# MIMXRT1052 register map
Vendor: nxp.com; File version: 1.0
CPU: CM7 r0p1, little endian, MPU, FPU, VTOR, 4 interrupt priority bits
Registers are 32-bit, read-write, reset 0x0 unless marked. A register's access mark holds for its fields unless they carry their own. Offsets are from the block's base; [hi:lo] are bit positions; {n}, {i} and the like mark numbered series; 'fields as' and 'values as' point back to an identical list.

## IOMUXC (part 4 of 4)
Base 0x401F8000; register names take the prefix IOMUXC_
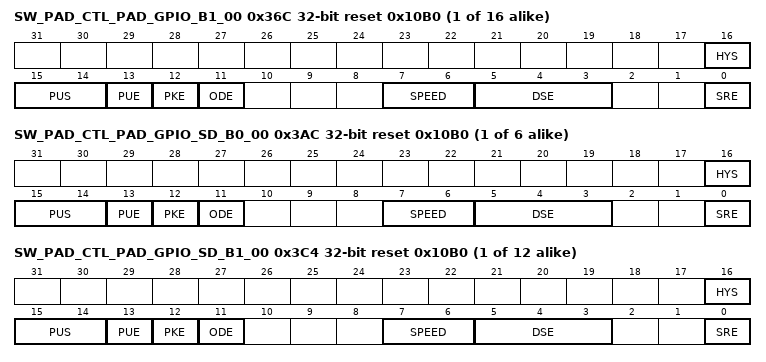
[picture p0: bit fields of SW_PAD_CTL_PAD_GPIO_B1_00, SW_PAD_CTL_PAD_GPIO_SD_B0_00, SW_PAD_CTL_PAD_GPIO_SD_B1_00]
{0x36C+4i} SW_PAD_CTL_PAD_GPIO_B1_{i:02} reset 0x10B0 (i=0..15) — SW_PAD_CTL_PAD_GPIO_B1_{i:02} SW PAD Control Register
  [16] HYS — Hyst. Enable Field
    0=HYS_0_Hysteresis_Disabled (Hysteresis Disabled (CMOS input)); 1=HYS_1_Hysteresis_Enabled (Hysteresis Enabled (Schmitt Trigger input))
  [15:14] PUS — Pull Up / Down Config. Field Controls signals to select pull-up or pull-down internal resistance strength.
    0=PUS_0_100K_Ohm_Pull_Down (100K Ohm Pull Down); 1=PUS_1_47K_Ohm_Pull_Up (47K Ohm Pull Up); 2=PUS_2_100K_Ohm_Pull_Up (100K Ohm Pull Up); 3=PUS_3_22K_Ohm_Pull_Up (22K Ohm Pull Up)
  [13] PUE — Pull / Keep Select Field Control signal to enable internal pull-up/down resistors or pad keeper functionality.
    0=PUE_0_Keeper (Keep the previous output value when the output driver is disabled.); 1=PUE_1_Pull (Pull-up or pull-down (determined by PUS field).)
  [12] PKE — Pull / Keep Enable Field
    0=PKE_0_Pull_Keeper_Disabled (Pull/Keeper Disabled); 1=PKE_1_Pull_Keeper_Enabled (Pull/Keeper Enabled)
  [11] ODE — Open Drain Enable Field
    0=ODE_0_Open_Drain_Disabled (Open Drain Disabled (Output is CMOS)); 1=ODE_1_Open_Drain_Enabled (Open Drain Enabled (Output is Open Drain))
  [7:6] SPEED
    0=SPEED_0_Low (50MHz); 1=SPEED_1_Medium (100MHz - 150MHz); 2=SPEED_2_Medium (100MHz - 150MHz); 3=SPEED_3_Maximum (150MHz - 200MHz)
  [5:3] DSE — Drive Strength Field
    0=HI-Z; 1=Dual/Single voltage: 262/260 Ohm @ 1.8V, 247/157 Ohm @ 3.3V; 2=Dual/Single voltage: 134/130 Ohm @ 1.8V, 126/78 Ohm @ 3.3V; 3=Dual/Single voltage: 88/88 Ohm @ 1.8V, 84/53 Ohm @ 3.3V; 4=Dual/Single voltage: 62/65 Ohm @ 1.8V, 57/39 Ohm @ 3.3V; 5=Dual/Single voltage: 51/52 Ohm @ 1.8V, 47/32 Ohm @ 3.3V; 6=Dual/Single voltage: 43/43 Ohm @ 1.8V, 40/26 Ohm @ 3.3V; 7=Dual/Single voltage: 37/37 Ohm @ 1.8V, 34/23 Ohm @ 3.3V
  [0] SRE — Slew Rate Field
    0=SRE_0_Slow_Slew_Rate (Slow Slew Rate); 1=SRE_1_Fast_Slew_Rate (Fast Slew Rate)
{0x3AC+4i} SW_PAD_CTL_PAD_GPIO_SD_B0_{i:02} reset 0x10B0 (i=0..5) — SW_PAD_CTL_PAD_GPIO_SD_B0_{i:02} SW PAD Control Register
  fields as SW_PAD_CTL_PAD_GPIO_B1_00
{0x3C4+4i} SW_PAD_CTL_PAD_GPIO_SD_B1_{i:02} reset 0x10B0 (i=0..11) — SW_PAD_CTL_PAD_GPIO_SD_B1_{i:02} SW PAD Control Register
  fields as SW_PAD_CTL_PAD_GPIO_B1_00
0x3F4 ANATOP_USB_OTG1_ID_SELECT_INPUT — ANATOP_USB_OTG1_ID_SELECT_INPUT DAISY Register
  [0] DAISY — Selecting Pads Involved in Daisy Chain.
    0=GPIO_AD_B0_01_ALT3 (Selecting Pad: GPIO_AD_B0_01 for Mode: ALT3); 1=GPIO_AD_B1_02_ALT0 (Selecting Pad: GPIO_AD_B1_02 for Mode: ALT0)
0x3F8 ANATOP_USB_OTG2_ID_SELECT_INPUT — ANATOP_USB_OTG2_ID_SELECT_INPUT DAISY Register
  [0] DAISY — Selecting Pads Involved in Daisy Chain.
    0=GPIO_AD_B0_00_ALT3 (Selecting Pad: GPIO_AD_B0_00 for Mode: ALT3); 1=GPIO_AD_B1_00_ALT0 (Selecting Pad: GPIO_AD_B1_00 for Mode: ALT0)
0x3FC CCM_PMIC_READY_SELECT_INPUT — CCM_PMIC_READY_SELECT_INPUT DAISY Register
  [2:0] DAISY — Selecting Pads Involved in Daisy Chain.
    0=GPIO_SD_B1_03_ALT6 (Selecting Pad: GPIO_SD_B1_03 for Mode: ALT6); 1=GPIO_AD_B0_12_ALT1 (Selecting Pad: GPIO_AD_B0_12 for Mode: ALT1); 2=GPIO_AD_B1_01_ALT4 (Selecting Pad: GPIO_AD_B1_01 for Mode: ALT4); 3=GPIO_AD_B1_08_ALT3 (Selecting Pad: GPIO_AD_B1_08 for Mode: ALT3); 4=GPIO_EMC_32_ALT3 (Selecting Pad: GPIO_EMC_32 for Mode: ALT3)
0x400 CSI_DATA02_SELECT_INPUT — CSI_DATA02_SELECT_INPUT DAISY Register
  [0] DAISY — Selecting Pads Involved in Daisy Chain.
    0=GPIO_AD_B1_15_ALT4 (Selecting Pad: GPIO_AD_B1_15 for Mode: ALT4); 1=GPIO_AD_B0_11_ALT4 (Selecting Pad: GPIO_AD_B0_11 for Mode: ALT4)
0x404 CSI_DATA03_SELECT_INPUT — CSI_DATA03_SELECT_INPUT DAISY Register
  [0] DAISY — Selecting Pads Involved in Daisy Chain.
    0=GPIO_AD_B1_14_ALT4 (Selecting Pad: GPIO_AD_B1_14 for Mode: ALT4); 1=GPIO_AD_B0_10_ALT4 (Selecting Pad: GPIO_AD_B0_10 for Mode: ALT4)
0x408 CSI_DATA04_SELECT_INPUT — CSI_DATA04_SELECT_INPUT DAISY Register
  [0] DAISY — Selecting Pads Involved in Daisy Chain.
    0=GPIO_AD_B1_13_ALT4 (Selecting Pad: GPIO_AD_B1_13 for Mode: ALT4); 1=GPIO_AD_B0_09_ALT4 (Selecting Pad: GPIO_AD_B0_09 for Mode: ALT4)
0x40C CSI_DATA05_SELECT_INPUT — CSI_DATA05_SELECT_INPUT DAISY Register
  [0] DAISY — Selecting Pads Involved in Daisy Chain.
    0=GPIO_AD_B1_12_ALT4 (Selecting Pad: GPIO_AD_B1_12 for Mode: ALT4); 1=GPIO_AD_B0_08_ALT4 (Selecting Pad: GPIO_AD_B0_08 for Mode: ALT4)
0x410 CSI_DATA06_SELECT_INPUT — CSI_DATA06_SELECT_INPUT DAISY Register
  [0] DAISY — Selecting Pads Involved in Daisy Chain.
    0=GPIO_AD_B1_11_ALT4 (Selecting Pad: GPIO_AD_B1_11 for Mode: ALT4); 1=GPIO_AD_B0_07_ALT4 (Selecting Pad: GPIO_AD_B0_07 for Mode: ALT4)
0x414 CSI_DATA07_SELECT_INPUT — CSI_DATA07_SELECT_INPUT DAISY Register
  [0] DAISY — Selecting Pads Involved in Daisy Chain.
    0=GPIO_AD_B1_10_ALT4 (Selecting Pad: GPIO_AD_B1_10 for Mode: ALT4); 1=GPIO_AD_B0_06_ALT4 (Selecting Pad: GPIO_AD_B0_06 for Mode: ALT4)
0x418 CSI_DATA08_SELECT_INPUT — CSI_DATA08_SELECT_INPUT DAISY Register
  [0] DAISY — Selecting Pads Involved in Daisy Chain.
    0=GPIO_AD_B1_09_ALT4 (Selecting Pad: GPIO_AD_B1_09 for Mode: ALT4); 1=GPIO_AD_B0_05_ALT4 (Selecting Pad: GPIO_AD_B0_05 for Mode: ALT4)
0x41C CSI_DATA09_SELECT_INPUT — CSI_DATA09_SELECT_INPUT DAISY Register
  [0] DAISY — Selecting Pads Involved in Daisy Chain.
    0=GPIO_AD_B1_08_ALT4 (Selecting Pad: GPIO_AD_B1_08 for Mode: ALT4); 1=GPIO_AD_B0_04_ALT4 (Selecting Pad: GPIO_AD_B0_04 for Mode: ALT4)
0x420 CSI_HSYNC_SELECT_INPUT — CSI_HSYNC_SELECT_INPUT DAISY Register
  [1:0] DAISY — Selecting Pads Involved in Daisy Chain.
    0=GPIO_AD_B0_15_ALT4 (Selecting Pad: GPIO_AD_B0_15 for Mode: ALT4); 1=GPIO_AD_B1_07_ALT4 (Selecting Pad: GPIO_AD_B1_07 for Mode: ALT4); 2=GPIO_B1_14_ALT2 (Selecting Pad: GPIO_B1_14 for Mode: ALT2)
0x424 CSI_PIXCLK_SELECT_INPUT — CSI_PIXCLK_SELECT_INPUT DAISY Register
  [0] DAISY — Selecting Pads Involved in Daisy Chain.
    0=GPIO_AD_B1_04_ALT4 (Selecting Pad: GPIO_AD_B1_04 for Mode: ALT4); 1=GPIO_B1_12_ALT2 (Selecting Pad: GPIO_B1_12 for Mode: ALT2)
0x428 CSI_VSYNC_SELECT_INPUT — CSI_VSYNC_SELECT_INPUT DAISY Register
  [1:0] DAISY — Selecting Pads Involved in Daisy Chain.
    0=GPIO_AD_B0_14_ALT4 (Selecting Pad: GPIO_AD_B0_14 for Mode: ALT4); 1=GPIO_AD_B1_06_ALT4 (Selecting Pad: GPIO_AD_B1_06 for Mode: ALT4); 2=GPIO_B1_13_ALT2 (Selecting Pad: GPIO_B1_13 for Mode: ALT2)
0x42C ENET_IPG_CLK_RMII_SELECT_INPUT — ENET_IPG_CLK_RMII_SELECT_INPUT DAISY Register
  [0] DAISY — Selecting Pads Involved in Daisy Chain.
    0=GPIO_EMC_25_ALT4 (Selecting Pad: GPIO_EMC_25 for Mode: ALT4); 1=GPIO_B1_10_ALT6 (Selecting Pad: GPIO_B1_10 for Mode: ALT6)
0x430 ENET_MDIO_SELECT_INPUT — ENET_MDIO_SELECT_INPUT DAISY Register
  [1:0] DAISY — Selecting Pads Involved in Daisy Chain.
    0=GPIO_AD_B1_05_ALT1 (Selecting Pad: GPIO_AD_B1_05 for Mode: ALT1); 1=GPIO_EMC_41_ALT4 (Selecting Pad: GPIO_EMC_41 for Mode: ALT4); 2=GPIO_B1_15_ALT0 (Selecting Pad: GPIO_B1_15 for Mode: ALT0)
0x434 ENET0_RXDATA_SELECT_INPUT — ENET0_RXDATA_SELECT_INPUT DAISY Register
  [0] DAISY — Selecting Pads Involved in Daisy Chain.
    0=GPIO_EMC_20_ALT3 (Selecting Pad: GPIO_EMC_20 for Mode: ALT3); 1=GPIO_B1_04_ALT3 (Selecting Pad: GPIO_B1_04 for Mode: ALT3)
0x438 ENET1_RXDATA_SELECT_INPUT — ENET1_RXDATA_SELECT_INPUT DAISY Register
  [0] DAISY — Selecting Pads Involved in Daisy Chain.
    0=GPIO_EMC_19_ALT3 (Selecting Pad: GPIO_EMC_19 for Mode: ALT3); 1=GPIO_B1_05_ALT3 (Selecting Pad: GPIO_B1_05 for Mode: ALT3)
0x43C ENET_RXEN_SELECT_INPUT — ENET_RXEN_SELECT_INPUT DAISY Register
  [0] DAISY — Selecting Pads Involved in Daisy Chain.
    0=GPIO_EMC_23_ALT3 (Selecting Pad: GPIO_EMC_23 for Mode: ALT3); 1=GPIO_B1_06_ALT3 (Selecting Pad: GPIO_B1_06 for Mode: ALT3)
0x440 ENET_RXERR_SELECT_INPUT — ENET_RXERR_SELECT_INPUT DAISY Register
  [0] DAISY — Selecting Pads Involved in Daisy Chain.
    0=GPIO_EMC_26_ALT3 (Selecting Pad: GPIO_EMC_26 for Mode: ALT3); 1=GPIO_B1_11_ALT3 (Selecting Pad: GPIO_B1_11 for Mode: ALT3)
0x444 ENET0_TIMER_SELECT_INPUT — ENET0_TIMER_SELECT_INPUT DAISY Register
  [1:0] DAISY — Selecting Pads Involved in Daisy Chain.
    0=GPIO_AD_B0_15_ALT3 (Selecting Pad: GPIO_AD_B0_15 for Mode: ALT3); 1=GPIO_AD_B0_11_ALT7 (Selecting Pad: GPIO_AD_B0_11 for Mode: ALT7); 2=GPIO_B1_12_ALT3 (Selecting Pad: GPIO_B1_12 for Mode: ALT3)
0x448 ENET_TXCLK_SELECT_INPUT — ENET_TXCLK_SELECT_INPUT DAISY Register
  [0] DAISY — Selecting Pads Involved in Daisy Chain.
    0=GPIO_EMC_25_ALT3 (Selecting Pad: GPIO_EMC_25 for Mode: ALT3); 1=GPIO_B1_10_ALT3 (Selecting Pad: GPIO_B1_10 for Mode: ALT3)
0x44C FLEXCAN1_RX_SELECT_INPUT — FLEXCAN1_RX_SELECT_INPUT DAISY Register
  [1:0] DAISY — Selecting Pads Involved in Daisy Chain.
    0=GPIO_SD_B1_03_ALT4 (Selecting Pad: GPIO_SD_B1_03 for Mode: ALT4); 1=GPIO_EMC_18_ALT3 (Selecting Pad: GPIO_EMC_18 for Mode: ALT3); 2=GPIO_AD_B1_09_ALT2 (Selecting Pad: GPIO_AD_B1_09 for Mode: ALT2); 3=GPIO_B0_03_ALT2 (Selecting Pad: GPIO_B0_03 for Mode: ALT2)
0x450 FLEXCAN2_RX_SELECT_INPUT — FLEXCAN2_RX_SELECT_INPUT DAISY Register
  [1:0] DAISY — Selecting Pads Involved in Daisy Chain.
    0=GPIO_EMC_10_ALT3 (Selecting Pad: GPIO_EMC_10 for Mode: ALT3); 1=GPIO_AD_B0_03_ALT0 (Selecting Pad: GPIO_AD_B0_03 for Mode: ALT0); 2=GPIO_AD_B0_15_ALT6 (Selecting Pad: GPIO_AD_B0_15 for Mode: ALT6); 3=GPIO_B1_09_ALT6 (Selecting Pad: GPIO_B1_09 for Mode: ALT6)
0x454 FLEXPWM1_PWMA3_SELECT_INPUT — FLEXPWM1_PWMA3_SELECT_INPUT DAISY Register
  [2:0] DAISY — Selecting Pads Involved in Daisy Chain.
    0=GPIO_SD_B1_00_ALT2 (Selecting Pad: GPIO_SD_B1_00 for Mode: ALT2); 1=GPIO_EMC_12_ALT4 (Selecting Pad: GPIO_EMC_12 for Mode: ALT4); 2=GPIO_EMC_38_ALT1 (Selecting Pad: GPIO_EMC_38 for Mode: ALT1); 3=GPIO_AD_B0_10_ALT1 (Selecting Pad: GPIO_AD_B0_10 for Mode: ALT1); 4=GPIO_B1_00_ALT6 (Selecting Pad: GPIO_B1_00 for Mode: ALT6)
{0x458+4i} FLEXPWM1_PWMA{i}_SELECT_INPUT (i=0..2) — FLEXPWM1_PWMA{i}_SELECT_INPUT DAISY Register
  [0] DAISY — Selecting Pads Involved in Daisy Chain.
    0=GPIO_EMC_{2i+23}_ALT1 (Selecting Pad: GPIO_EMC_{2i+23} for Mode: ALT1); 1=GPIO_SD_B0_{2i:02}_ALT1 (Selecting Pad: GPIO_SD_B0_{2i:02} for Mode: ALT1)
0x464 FLEXPWM1_PWMB3_SELECT_INPUT — FLEXPWM1_PWMB3_SELECT_INPUT DAISY Register
  [2:0] DAISY — Selecting Pads Involved in Daisy Chain.
    0=GPIO_SD_B1_01_ALT2 (Selecting Pad: GPIO_SD_B1_01 for Mode: ALT2); 1=GPIO_EMC_13_ALT4 (Selecting Pad: GPIO_EMC_13 for Mode: ALT4); 2=GPIO_EMC_39_ALT1 (Selecting Pad: GPIO_EMC_39 for Mode: ALT1); 3=GPIO_AD_B0_11_ALT1 (Selecting Pad: GPIO_AD_B0_11 for Mode: ALT1); 4=GPIO_B1_01_ALT6 (Selecting Pad: GPIO_B1_01 for Mode: ALT6)
{0x468+4i} FLEXPWM1_PWMB{i}_SELECT_INPUT (i=0..2) — FLEXPWM1_PWMB{i}_SELECT_INPUT DAISY Register
  [0] DAISY — Selecting Pads Involved in Daisy Chain.
    0=GPIO_EMC_{2i+24}_ALT1 (Selecting Pad: GPIO_EMC_{2i+24} for Mode: ALT1); 1=GPIO_SD_B0_{2i+1:02}_ALT1 (Selecting Pad: GPIO_SD_B0_{2i+1:02} for Mode: ALT1)
0x474 FLEXPWM2_PWMA3_SELECT_INPUT — FLEXPWM2_PWMA3_SELECT_INPUT DAISY Register
  [2:0] DAISY — Selecting Pads Involved in Daisy Chain.
    0=GPIO_SD_B1_02_ALT2 (Selecting Pad: GPIO_SD_B1_02 for Mode: ALT2); 1=GPIO_EMC_19_ALT1 (Selecting Pad: GPIO_EMC_19 for Mode: ALT1); 2=GPIO_AD_B0_00_ALT0 (Selecting Pad: GPIO_AD_B0_00 for Mode: ALT0); 3=GPIO_AD_B0_09_ALT1 (Selecting Pad: GPIO_AD_B0_09 for Mode: ALT1); 4=GPIO_B1_02_ALT6 (Selecting Pad: GPIO_B1_02 for Mode: ALT6)
{0x478+4i} FLEXPWM2_PWMA{i}_SELECT_INPUT (i=0..2) — FLEXPWM2_PWMA{i}_SELECT_INPUT DAISY Register
  [0] DAISY — Selecting Pads Involved in Daisy Chain.
    0=GPIO_EMC_{2i+6:02}_ALT1 (Selecting Pad: GPIO_EMC_{2i+6:02} for Mode: ALT1); 1=GPIO_B0_{2i+6:02}_ALT2 (Selecting Pad: GPIO_B0_{2i+6:02} for Mode: ALT2)
0x484 FLEXPWM2_PWMB3_SELECT_INPUT — FLEXPWM2_PWMB3_SELECT_INPUT DAISY Register
  [1:0] DAISY — Selecting Pads Involved in Daisy Chain.
    0=GPIO_SD_B1_03_ALT2 (Selecting Pad: GPIO_SD_B1_03 for Mode: ALT2); 1=GPIO_EMC_20_ALT1 (Selecting Pad: GPIO_EMC_20 for Mode: ALT1); 2=GPIO_AD_B0_01_ALT0 (Selecting Pad: GPIO_AD_B0_01 for Mode: ALT0); 3=GPIO_B1_03_ALT6 (Selecting Pad: GPIO_B1_03 for Mode: ALT6)
{0x488+4i} FLEXPWM2_PWMB{i}_SELECT_INPUT (i=0..2) — FLEXPWM2_PWMB{i}_SELECT_INPUT DAISY Register
  [0] DAISY — Selecting Pads Involved in Daisy Chain.
    0=GPIO_EMC_{2i+7:02}_ALT1 (Selecting Pad: GPIO_EMC_{2i+7:02} for Mode: ALT1); 1=GPIO_B0_{2i+7:02}_ALT2 (Selecting Pad: GPIO_B0_{2i+7:02} for Mode: ALT2)
0x494 FLEXPWM4_PWMA0_SELECT_INPUT — FLEXPWM4_PWMA0_SELECT_INPUT DAISY Register
  [0] DAISY — Selecting Pads Involved in Daisy Chain.
    0=GPIO_EMC_00_ALT1 (Selecting Pad: GPIO_EMC_00 for Mode: ALT1); 1=GPIO_AD_B1_08_ALT1 (Selecting Pad: GPIO_AD_B1_08 for Mode: ALT1)
0x498 FLEXPWM4_PWMA1_SELECT_INPUT — FLEXPWM4_PWMA1_SELECT_INPUT DAISY Register
  [0] DAISY — Selecting Pads Involved in Daisy Chain.
    0=GPIO_EMC_02_ALT1 (Selecting Pad: GPIO_EMC_02 for Mode: ALT1); 1=GPIO_AD_B1_09_ALT1 (Selecting Pad: GPIO_AD_B1_09 for Mode: ALT1)
0x49C FLEXPWM4_PWMA2_SELECT_INPUT — FLEXPWM4_PWMA2_SELECT_INPUT DAISY Register
  [0] DAISY — Selecting Pads Involved in Daisy Chain.
    0=GPIO_EMC_04_ALT1 (Selecting Pad: GPIO_EMC_04 for Mode: ALT1); 1=GPIO_B1_14_ALT1 (Selecting Pad: GPIO_B1_14 for Mode: ALT1)
0x4A0 FLEXPWM4_PWMA3_SELECT_INPUT — FLEXPWM4_PWMA3_SELECT_INPUT DAISY Register
  [0] DAISY — Selecting Pads Involved in Daisy Chain.
    0=GPIO_EMC_17_ALT1 (Selecting Pad: GPIO_EMC_17 for Mode: ALT1); 1=GPIO_B1_15_ALT1 (Selecting Pad: GPIO_B1_15 for Mode: ALT1)
0x4A4 FLEXSPI_A_DQS_SELECT_INPUT — FLEXSPI_A_DQS_SELECT_INPUT DAISY Register
  [0] DAISY — Selecting Pads Involved in Daisy Chain.
    0=GPIO_SD_B1_05_ALT1 (Selecting Pad: GPIO_SD_B1_05 for Mode: ALT1); 1=GPIO_AD_B1_09_ALT0 (Selecting Pad: GPIO_AD_B1_09 for Mode: ALT0)
0x4A8 FLEXSPI_A_DATA0_SELECT_INPUT — FLEXSPI_A_DATA0_SELECT_INPUT DAISY Register
  [0] DAISY — Selecting Pads Involved in Daisy Chain.
    0=GPIO_SD_B1_08_ALT1 (Selecting Pad: GPIO_SD_B1_08 for Mode: ALT1); 1=GPIO_AD_B1_13_ALT0 (Selecting Pad: GPIO_AD_B1_13 for Mode: ALT0)
0x4AC FLEXSPI_A_DATA1_SELECT_INPUT — FLEXSPI_A_DATA1_SELECT_INPUT DAISY Register
  [0] DAISY — Selecting Pads Involved in Daisy Chain.
    0=GPIO_SD_B1_09_ALT1 (Selecting Pad: GPIO_SD_B1_09 for Mode: ALT1); 1=GPIO_AD_B1_12_ALT0 (Selecting Pad: GPIO_AD_B1_12 for Mode: ALT0)
0x4B0 FLEXSPI_A_DATA2_SELECT_INPUT — FLEXSPI_A_DATA2_SELECT_INPUT DAISY Register
  [0] DAISY — Selecting Pads Involved in Daisy Chain.
    0=GPIO_SD_B1_10_ALT1 (Selecting Pad: GPIO_SD_B1_10 for Mode: ALT1); 1=GPIO_AD_B1_11_ALT0 (Selecting Pad: GPIO_AD_B1_11 for Mode: ALT0)
0x4B4 FLEXSPI_A_DATA3_SELECT_INPUT — FLEXSPI_A_DATA3_SELECT_INPUT DAISY Register
  [0] DAISY — Selecting Pads Involved in Daisy Chain.
    0=GPIO_SD_B1_11_ALT1 (Selecting Pad: GPIO_SD_B1_11 for Mode: ALT1); 1=GPIO_AD_B1_10_ALT0 (Selecting Pad: GPIO_AD_B1_10 for Mode: ALT0)
0x4B8 FLEXSPI_B_DATA0_SELECT_INPUT — FLEXSPI_B_DATA0_SELECT_INPUT DAISY Register
  [0] DAISY — Selecting Pads Involved in Daisy Chain.
    0=GPIO_SD_B1_03_ALT1 (Selecting Pad: GPIO_SD_B1_03 for Mode: ALT1); 1=GPIO_AD_B1_07_ALT0 (Selecting Pad: GPIO_AD_B1_07 for Mode: ALT0)
0x4BC FLEXSPI_B_DATA1_SELECT_INPUT — FLEXSPI_B_DATA1_SELECT_INPUT DAISY Register
  [0] DAISY — Selecting Pads Involved in Daisy Chain.
    0=GPIO_SD_B1_02_ALT1 (Selecting Pad: GPIO_SD_B1_02 for Mode: ALT1); 1=GPIO_AD_B1_06_ALT0 (Selecting Pad: GPIO_AD_B1_06 for Mode: ALT0)
0x4C0 FLEXSPI_B_DATA2_SELECT_INPUT — FLEXSPI_B_DATA2_SELECT_INPUT DAISY Register
  [0] DAISY — Selecting Pads Involved in Daisy Chain.
    0=GPIO_SD_B1_01_ALT1 (Selecting Pad: GPIO_SD_B1_01 for Mode: ALT1); 1=GPIO_AD_B1_05_ALT0 (Selecting Pad: GPIO_AD_B1_05 for Mode: ALT0)
0x4C4 FLEXSPI_B_DATA3_SELECT_INPUT — FLEXSPI_B_DATA3_SELECT_INPUT DAISY Register
  [0] DAISY — Selecting Pads Involved in Daisy Chain.
    0=GPIO_SD_B1_00_ALT1 (Selecting Pad: GPIO_SD_B1_00 for Mode: ALT1); 1=GPIO_AD_B1_04_ALT0 (Selecting Pad: GPIO_AD_B1_04 for Mode: ALT0)
0x4C8 FLEXSPI_A_SCK_SELECT_INPUT — FLEXSPI_A_SCK_SELECT_INPUT DAISY Register
  [0] DAISY — Selecting Pads Involved in Daisy Chain.
    0=GPIO_SD_B1_07_ALT1 (Selecting Pad: GPIO_SD_B1_07 for Mode: ALT1); 1=GPIO_AD_B1_14_ALT0 (Selecting Pad: GPIO_AD_B1_14 for Mode: ALT0)
0x4CC LPI2C1_SCL_SELECT_INPUT — LPI2C1_SCL_SELECT_INPUT DAISY Register
  [0] DAISY — Selecting Pads Involved in Daisy Chain.
    0=GPIO_SD_B1_04_ALT2 (Selecting Pad: GPIO_SD_B1_04 for Mode: ALT2); 1=GPIO_AD_B1_00_ALT3 (Selecting Pad: GPIO_AD_B1_00 for Mode: ALT3)
0x4D0 LPI2C1_SDA_SELECT_INPUT — LPI2C1_SDA_SELECT_INPUT DAISY Register
  [0] DAISY — Selecting Pads Involved in Daisy Chain.
    0=GPIO_SD_B1_05_ALT2 (Selecting Pad: GPIO_SD_B1_05 for Mode: ALT2); 1=GPIO_AD_B1_01_ALT3 (Selecting Pad: GPIO_AD_B1_01 for Mode: ALT3)
0x4D4 LPI2C2_SCL_SELECT_INPUT — LPI2C2_SCL_SELECT_INPUT DAISY Register
  [0] DAISY — Selecting Pads Involved in Daisy Chain.
    0=GPIO_SD_B1_11_ALT3 (Selecting Pad: GPIO_SD_B1_11 for Mode: ALT3); 1=GPIO_B0_04_ALT2 (Selecting Pad: GPIO_B0_04 for Mode: ALT2)
0x4D8 LPI2C2_SDA_SELECT_INPUT — LPI2C2_SDA_SELECT_INPUT DAISY Register
  [0] DAISY — Selecting Pads Involved in Daisy Chain.
    0=GPIO_SD_B1_10_ALT3 (Selecting Pad: GPIO_SD_B1_10 for Mode: ALT3); 1=GPIO_B0_05_ALT2 (Selecting Pad: GPIO_B0_05 for Mode: ALT2)
0x4DC LPI2C3_SCL_SELECT_INPUT — LPI2C3_SCL_SELECT_INPUT DAISY Register
  [1:0] DAISY — Selecting Pads Involved in Daisy Chain.
    0=GPIO_EMC_22_ALT2 (Selecting Pad: GPIO_EMC_22 for Mode: ALT2); 1=GPIO_SD_B0_00_ALT2 (Selecting Pad: GPIO_SD_B0_00 for Mode: ALT2); 2=GPIO_AD_B1_07_ALT1 (Selecting Pad: GPIO_AD_B1_07 for Mode: ALT1)
0x4E0 LPI2C3_SDA_SELECT_INPUT — LPI2C3_SDA_SELECT_INPUT DAISY Register
  [1:0] DAISY — Selecting Pads Involved in Daisy Chain.
    0=GPIO_EMC_21_ALT2 (Selecting Pad: GPIO_EMC_21 for Mode: ALT2); 1=GPIO_SD_B0_01_ALT2 (Selecting Pad: GPIO_SD_B0_01 for Mode: ALT2); 2=GPIO_AD_B1_06_ALT1 (Selecting Pad: GPIO_AD_B1_06 for Mode: ALT1)
0x4E4 LPI2C4_SCL_SELECT_INPUT — LPI2C4_SCL_SELECT_INPUT DAISY Register
  [0] DAISY — Selecting Pads Involved in Daisy Chain.
    0=GPIO_EMC_12_ALT2 (Selecting Pad: GPIO_EMC_12 for Mode: ALT2); 1=GPIO_AD_B0_12_ALT0 (Selecting Pad: GPIO_AD_B0_12 for Mode: ALT0)
0x4E8 LPI2C4_SDA_SELECT_INPUT — LPI2C4_SDA_SELECT_INPUT DAISY Register
  [0] DAISY — Selecting Pads Involved in Daisy Chain.
    0=GPIO_EMC_11_ALT2 (Selecting Pad: GPIO_EMC_11 for Mode: ALT2); 1=GPIO_AD_B0_13_ALT0 (Selecting Pad: GPIO_AD_B0_13 for Mode: ALT0)
0x4EC LPSPI1_PCS0_SELECT_INPUT — LPSPI1_PCS0_SELECT_INPUT DAISY Register
  [0] DAISY — Selecting Pads Involved in Daisy Chain.
    0=GPIO_SD_B0_01_ALT4 (Selecting Pad: GPIO_SD_B0_01 for Mode: ALT4); 1=GPIO_EMC_30_ALT3 (Selecting Pad: GPIO_EMC_30 for Mode: ALT3)
0x4F0 LPSPI1_SCK_SELECT_INPUT — LPSPI1_SCK_SELECT_INPUT DAISY Register
  [0] DAISY — Selecting Pads Involved in Daisy Chain.
    0=GPIO_EMC_27_ALT3 (Selecting Pad: GPIO_EMC_27 for Mode: ALT3); 1=GPIO_SD_B0_00_ALT4 (Selecting Pad: GPIO_SD_B0_00 for Mode: ALT4)
0x4F4 LPSPI1_SDI_SELECT_INPUT — LPSPI1_SDI_SELECT_INPUT DAISY Register
  [0] DAISY — Selecting Pads Involved in Daisy Chain.
    0=GPIO_EMC_29_ALT3 (Selecting Pad: GPIO_EMC_29 for Mode: ALT3); 1=GPIO_SD_B0_03_ALT4 (Selecting Pad: GPIO_AD_B0_03 for Mode: ALT4)
0x4F8 LPSPI1_SDO_SELECT_INPUT — LPSPI1_SDO_SELECT_INPUT DAISY Register
  [0] DAISY — Selecting Pads Involved in Daisy Chain.
    0=GPIO_EMC_28_ALT3 (Selecting Pad: GPIO_EMC_28 for Mode: ALT3); 1=GPIO_SD_B0_02_ALT4 (Selecting Pad: GPIO_SD_B0_02 for Mode: ALT4)
0x4FC LPSPI2_PCS0_SELECT_INPUT — LPSPI2_PCS0_SELECT_INPUT DAISY Register
  [0] DAISY — Selecting Pads Involved in Daisy Chain.
    0=GPIO_SD_B1_06_ALT4 (Selecting Pad: GPIO_SD_B1_06 for Mode: ALT4); 1=GPIO_EMC_01_ALT2 (Selecting Pad: GPIO_EMC_01 for Mode: ALT2)
0x500 LPSPI2_SCK_SELECT_INPUT — LPSPI2_SCK_SELECT_INPUT DAISY Register
  [0] DAISY — Selecting Pads Involved in Daisy Chain.
    0=GPIO_SD_B1_07_ALT4 (Selecting Pad: GPIO_SD_B1_07 for Mode: ALT4); 1=GPIO_EMC_00_ALT2 (Selecting Pad: GPIO_EMC_00 for Mode: ALT2)
0x504 LPSPI2_SDI_SELECT_INPUT — LPSPI2_SDI_SELECT_INPUT DAISY Register
  [0] DAISY — Selecting Pads Involved in Daisy Chain.
    0=GPIO_SD_B1_09_ALT4 (Selecting Pad: GPIO_SD_B1_09 for Mode: ALT4); 1=GPIO_EMC_03_ALT2 (Selecting Pad: GPIO_EMC_03 for Mode: ALT2)
0x508 LPSPI2_SDO_SELECT_INPUT — LPSPI2_SDO_SELECT_INPUT DAISY Register
  [0] DAISY — Selecting Pads Involved in Daisy Chain.
    0=GPIO_SD_B1_08_ALT4 (Selecting Pad: GPIO_SD_B1_08 for Mode: ALT4); 1=GPIO_EMC_02_ALT2 (Selecting Pad: GPIO_EMC_02 for Mode: ALT2)
0x50C LPSPI3_PCS0_SELECT_INPUT — LPSPI3_PCS0_SELECT_INPUT DAISY Register
  [0] DAISY — Selecting Pads Involved in Daisy Chain.
    0=GPIO_AD_B0_03_ALT7 (Selecting Pad: GPIO_AD_B0_03 for Mode: ALT7); 1=GPIO_AD_B1_12_ALT2 (Selecting Pad: GPIO_AD_B1_12 for Mode: ALT2)
0x510 LPSPI3_SCK_SELECT_INPUT — LPSPI3_SCK_SELECT_INPUT DAISY Register
  [0] DAISY — Selecting Pads Involved in Daisy Chain.
    0=GPIO_AD_B0_00_ALT7 (Selecting Pad: GPIO_AD_B0_00 for Mode: ALT7); 1=GPIO_AD_B1_15 (Selecting Pad: GPIO_AD_B1_15 for Mode: ALT2)
0x514 LPSPI3_SDI_SELECT_INPUT — LPSPI3_SDI_SELECT_INPUT DAISY Register
  [0] DAISY — Selecting Pads Involved in Daisy Chain.
    0=GPIO_AD_B0_02_ALT7 (Selecting Pad: GPIO_AD_B0_02 for Mode: ALT7); 1=GPIO_AD_B1_13_ALT2 (Selecting Pad: GPIO_AD_B1_13 for Mode: ALT2)
0x518 LPSPI3_SDO_SELECT_INPUT — LPSPI3_SDO_SELECT_INPUT DAISY Register
  [0] DAISY — Selecting Pads Involved in Daisy Chain.
    0=GPIO_AD_B0_01_ALT7 (Selecting Pad: GPIO_AD_B0_01 for Mode: ALT7); 1=GPIO_AD_B1_14_ALT2 (Selecting Pad: GPIO_AD_B1_14 for Mode: ALT2)
0x51C LPSPI4_PCS0_SELECT_INPUT — LPSPI4_PCS0_SELECT_INPUT DAISY Register
  [0] DAISY — Selecting Pads Involved in Daisy Chain.
    0=GPIO_B0_00_ALT3 (Selecting Pad: GPIO_B0_00 for Mode: ALT3); 1=GPIO_B1_04_ALT1 (Selecting Pad:GPIO_B1_04 for Mode: ALT1)
0x520 LPSPI4_SCK_SELECT_INPUT — LPSPI4_SCK_SELECT_INPUT DAISY Register
  [0] DAISY — Selecting Pads Involved in Daisy Chain.
    0=GPIO_B0_03_ALT3 (Selecting Pad: GPIO_B0_03 for Mode: ALT3); 1=GPIO_B1_07_ALT1 (Selecting Pad: GPIO_B1_07 for Mode: ALT1)
0x524 LPSPI4_SDI_SELECT_INPUT — LPSPI4_SDI_SELECT_INPUT DAISY Register
  [0] DAISY — Selecting Pads Involved in Daisy Chain.
    0=GPIO_B0_01_ALT3 (Selecting Pad: GPIO_B0_01 for Mode: ALT3); 1=GPIO_B1_05_ALT1 (Selecting Pad: GPIO_B1_05 for Mode: ALT1)
0x528 LPSPI4_SDO_SELECT_INPUT — LPSPI4_SDO_SELECT_INPUT DAISY Register
  [0] DAISY — Selecting Pads Involved in Daisy Chain.
    0=GPIO_B0_02_ALT3 (Selecting Pad: GPIO_B0_02 for Mode: ALT3); 1=GPIO_B1_06_ALT1 (Selecting Pad: GPIO_B1_06 for Mode: ALT1)
0x52C LPUART2_RX_SELECT_INPUT — LPUART2_RX_SELECT_INPUT DAISY Register
  [0] DAISY — Selecting Pads Involved in Daisy Chain.
    0=GPIO_SD_B1_10_ALT2 (Selecting Pad: GPIO_SD_B1_10 for Mode: ALT2); 1=GPIO_AD_B1_03_ALT2 (Selecting Pad: GPIO_AD_B1_03 for Mode: ALT2)
0x530 LPUART2_TX_SELECT_INPUT — LPUART2_TX_SELECT_INPUT DAISY Register
  [0] DAISY — Selecting Pads Involved in Daisy Chain.
    0=GPIO_SD_B1_11_ALT2 (Selecting Pad: GPIO_SD_B1_11 for Mode: ALT2); 1=GPIO_AD_B1_02_ALT2 (Selecting Pad: GPIO_AD_B1_02 for Mode: ALT2)
0x534 LPUART3_CTS_B_SELECT_INPUT — LPUART3_CTS_B_SELECT_INPUT DAISY Register
  [0] DAISY — Selecting Pads Involved in Daisy Chain.
    0=GPIO_EMC_15_ALT2 (Selecting Pad: GPIO_EMC_15 for Mode: ALT2); 1=GPIO_AD_B1_04_ALT2 (Selecting Pad: GPIO_AD_B1_04 for Mode: ALT2)
0x538 LPUART3_RX_SELECT_INPUT — LPUART3_RX_SELECT_INPUT DAISY Register
  [1:0] DAISY — Selecting Pads Involved in Daisy Chain.
    0=GPIO_AD_B1_07_ALT2 (Selecting Pad: GPIO_AD_B1_07 for Mode: ALT2); 1=GPIO_EMC_14_ALT2 (Selecting Pad: GPIO_EMC_14 for Mode: ALT2); 2=GPIO_B0_09_ALT3 (Selecting Pad: GPIO_B0_09 for Mode: ALT3)
0x53C LPUART3_TX_SELECT_INPUT — LPUART3_TX_SELECT_INPUT DAISY Register
  [1:0] DAISY — Selecting Pads Involved in Daisy Chain.
    0=GPIO_AD_B1_06_ALT2 (Selecting Pad: GPIO_AD_B1_06 for Mode: ALT2); 1=GPIO_EMC_13_ALT2 (Selecting Pad: GPIO_EMC_13 for Mode: ALT2); 2=GPIO_B0_08_ALT3 (Selecting Pad: GPIO_B0_08 for Mode: ALT3)
0x540 LPUART4_RX_SELECT_INPUT — LPUART4_RX_SELECT_INPUT DAISY Register
  [1:0] DAISY — Selecting Pads Involved in Daisy Chain.
    0=GPIO_SD_B1_01_ALT4 (Selecting Pad: GPIO_SD_B1_01 for Mode: ALT4); 1=GPIO_EMC_20_ALT2 (Selecting Pad: GPIO_EMC_20 for Mode: ALT2); 2=GPIO_B1_01_ALT2 (Selecting Pad: GPIO_B1_01 for Mode: ALT2)
0x544 LPUART4_TX_SELECT_INPUT — LPUART4_TX_SELECT_INPUT DAISY Register
  [1:0] DAISY — Selecting Pads Involved in Daisy Chain.
    0=GPIO_SD_B1_00_ALT4 (Selecting Pad: GPIO_SD_B1_00 for Mode: ALT4); 1=GPIO_EMC_19_ALT2 (Selecting Pad: GPIO_EMC_19 for Mode: ALT2); 2=GPIO_B1_00_ALT2 (Selecting Pad: GPIO_B1_00 for Mode: ALT2)
0x548 LPUART5_RX_SELECT_INPUT — LPUART5_RX_SELECT_INPUT DAISY Register
  [0] DAISY — Selecting Pads Involved in Daisy Chain.
    0=GPIO_EMC_24_ALT2 (Selecting Pad: GPIO_EMC_24 for Mode: ALT2); 1=GPIO_B1_13_ALT1 (Selecting Pad: GPIO_B1_13 for Mode: ALT1)
0x54C LPUART5_TX_SELECT_INPUT — LPUART5_TX_SELECT_INPUT DAISY Register
  [0] DAISY — Selecting Pads Involved in Daisy Chain.
    0=GPIO_EMC_23_ALT2 (Selecting Pad: GPIO_EMC_23 for Mode: ALT2); 1=GPIO_B1_12_ALT1 (Selecting Pad: GPIO_B1_12 for Mode: ALT1)
0x550 LPUART6_RX_SELECT_INPUT — LPUART6_RX_SELECT_INPUT DAISY Register
  [0] DAISY — Selecting Pads Involved in Daisy Chain.
    0=GPIO_EMC_26_ALT2 (Selecting Pad: GPIO_EMC_26 for Mode: ALT2); 1=GPIO_AD_B0_03_ALT2 (Selecting Pad: GPIO_AD_B0_03 for Mode: ALT2)
0x554 LPUART6_TX_SELECT_INPUT — LPUART6_TX_SELECT_INPUT DAISY Register
  [0] DAISY — Selecting Pads Involved in Daisy Chain.
    0=GPIO_EMC_25_ALT2 (Selecting Pad: GPIO_EMC_25 for Mode: ALT2); 1=GPIO_AD_B0_02_ALT2 (Selecting Pad: GPIO_AD_B0_02 for Mode: ALT2)
0x558 LPUART7_RX_SELECT_INPUT — LPUART7_RX_SELECT_INPUT DAISY Register
  [0] DAISY — Selecting Pads Involved in Daisy Chain.
    0=GPIO_SD_B1_09_ALT2 (Selecting Pad: GPIO_SD_B1_09 for Mode: ALT2); 1=GPIO_EMC_32_ALT2 (Selecting Pad: GPIO_EMC_32 for Mode: ALT2)
0x55C LPUART7_TX_SELECT_INPUT — LPUART7_TX_SELECT_INPUT DAISY Register
  [0] DAISY — Selecting Pads Involved in Daisy Chain.
    0=GPIO_SD_B1_08_ALT2 (Selecting Pad: GPIO_SD_B1_08 for Mode: ALT2); 1=GPIO_EMC_31_ALT2 (Selecting Pad:GPIO_EMC_31 for Mode: ALT2)
0x560 LPUART8_RX_SELECT_INPUT — LPUART8_RX_SELECT_INPUT DAISY Register
  [1:0] DAISY — Selecting Pads Involved in Daisy Chain.
    0=GPIO_SD_B0_05_ALT2 (Selecting Pad: GPIO_SD_B0_05 for Mode: ALT2); 1=GPIO_AD_B1_11_ALT2 (Selecting Pad: GPIO_AD_B1_11 for Mode: ALT2); 2=GPIO_EMC_39_ALT2 (Selecting Pad: GPIO_EMC_39 for Mode: ALT2)
0x564 LPUART8_TX_SELECT_INPUT — LPUART8_TX_SELECT_INPUT DAISY Register
  [1:0] DAISY — Selecting Pads Involved in Daisy Chain.
    0=GPIO_SD_B0_04_ALT2 (Selecting Pad: GPIO_SD_B0_04 for Mode: ALT2); 1=GPIO_AD_B1_10_ALT2 (Selecting Pad: GPIO_AD_B1_10 for Mode: ALT2); 2=GPIO_EMC_38_ALT2 (Selecting Pad: GPIO_EMC_38 for Mode: ALT2)
0x568 NMI_SELECT_INPUT — NMI_SELECT_INPUT DAISY Register
  [0] DAISY — Selecting Pads Involved in Daisy Chain.
    0=GPIO_AD_B0_12_ALT7 (Selecting Pad: GPIO_AD_B0_12 for Mode: ALT7); 1=WAKEUP_ALT7 (Selecting Pad: WAKEUP for Mode: ALT7)
{0x56C+4i} QTIMER2_TIMER{i}_SELECT_INPUT (i=0..2) — QTIMER2_TIMER{i}_SELECT_INPUT DAISY Register
  [0] DAISY — Selecting Pads Involved in Daisy Chain.
    0=GPIO_EMC_{i+19}_ALT4 (Selecting Pad: GPIO_EMC_{i+19} for Mode: ALT4); 1=GPIO_B0_{i+3:02}_ALT1 (Selecting Pad: GPIO_B0_{i+3:02} for Mode: ALT1)
0x578 QTIMER2_TIMER3_SELECT_INPUT — QTIMER2_TIMER3_SELECT_INPUT DAISY Register
  [0] DAISY — Selecting Pads Involved in Daisy Chain.
    0=GPIO_EMC_22_ALT4 (Selecting Pad: GPIO_EMC_22 for Mode: ALT4); 1=GPIO_B1_09_ALT1 (Selecting Pad: GPIO_B1_09 for Mode: ALT1)
0x57C QTIMER3_TIMER0_SELECT_INPUT — QTIMER3_TIMER0_SELECT_INPUT DAISY Register
  [1:0] DAISY — Selecting Pads Involved in Daisy Chain.
    0=GPIO_EMC_15_ALT4 (Selecting Pad: GPIO_EMC_15 for Mode: ALT4); 1=GPIO_AD_B1_00_ALT1 (Selecting Pad: GPIO_AD_B1_00 for Mode: ALT1); 2=GPIO_B0_06_ALT1 (Selecting Pad: GPIO_B0_06 for Mode: ALT1)
0x580 QTIMER3_TIMER1_SELECT_INPUT — QTIMER3_TIMER1_SELECT_INPUT DAISY Register
  [1:0] DAISY — Selecting Pads Involved in Daisy Chain.
    0=GPIO_AD_B1_01_ALT1 (Selecting Pad: GPIO_AD_B1_01 for Mode: ALT1); 1=GPIO_EMC_16_ALT4 (Selecting Pad: GPIO_EMC_16 for Mode: ALT4); 2=GPIO_B0_07_ALT1 (Selecting Pad: GPIO_B0_07 for Mode: ALT1)
0x584 QTIMER3_TIMER2_SELECT_INPUT — QTIMER3_TIMER2_SELECT_INPUT DAISY Register
  [1:0] DAISY — Selecting Pads Involved in Daisy Chain.
    0=GPIO_EMC_17_ALT4 (Selecting Pad: GPIO_EMC_17 for Mode: ALT4); 1=GPIO_AD_B1_02_ALT1 (Selecting Pad: GPIO_AD_B1_02 for Mode: ALT1); 2=GPIO_B0_08_ALT1 (Selecting Pad: GPIO_B0_08 for Mode: ALT1)
0x588 QTIMER3_TIMER3_SELECT_INPUT — QTIMER3_TIMER3_SELECT_INPUT DAISY Register
  [1:0] DAISY — Selecting Pads Involved in Daisy Chain.
    0=GPIO_EMC_18_ALT4 (Selecting Pad: GPIO_EMC_18 for Mode: ALT4); 1=GPIO_AD_B1_03_ALT1 (Selecting Pad: GPIO_AD_B1_03 for Mode: ALT1); 2=GPIO_B1_10_ALT1 (Selecting Pad: GPIO_B1_10 for Mode: ALT1)
0x58C SAI1_MCLK2_SELECT_INPUT — SAI1_MCLK2_SELECT_INPUT DAISY Register
  [1:0] DAISY — Selecting Pads Involved in Daisy Chain.
    0=GPIO_SD_B1_03_ALT3 (Selecting Pad: GPIO_SD_B1_03 for Mode: ALT3); 1=GPIO_AD_B1_09_ALT3 (Selecting Pad: GPIO_AD_B1_09 for Mode: ALT3); 2=GPIO_B0_13_ALT3 (Selecting Pad: GPIO_B0_13 for Mode: ALT3)
0x590 SAI1_RX_BCLK_SELECT_INPUT — SAI1_RX_BCLK_SELECT_INPUT DAISY Register
  [1:0] DAISY — Selecting Pads Involved in Daisy Chain.
    0=GPIO_SD_B1_05_ALT3 (Selecting Pad: GPIO_SD_B1_05 for Mode: ALT3); 1=GPIO_AD_B1_11_ALT3 (Selecting Pad: GPIO_AD_B1_11 for Mode: ALT3); 2=GPIO_B0_15_ALT3 (Selecting Pad: GPIO_B0_15 for Mode: ALT3)
0x594 SAI1_RX_DATA0_SELECT_INPUT — SAI1_RX_DATA0_SELECT_INPUT DAISY Register
  [1:0] DAISY — Selecting Pads Involved in Daisy Chain.
    0=GPIO_SD_B1_06_ALT3 (Selecting Pad: GPIO_SD_B1_06 for Mode: ALT3); 1=GPIO_AD_B1_12_ALT3 (Selecting Pad: GPIO_AD_B1_12 for Mode: ALT3); 2=GPIO_B1_00_ALT3 (Selecting Pad: GPIO_B1_00 for Mode: ALT3)
{0x594+4i} SAI1_RX_DATA{i}_SELECT_INPUT (i=1..3) — SAI1_RX_DATA{i}_SELECT_INPUT DAISY Register
  [0] DAISY — Selecting Pads Involved in Daisy Chain.
    0=GPIO_SD_B1_{i-1:02}_ALT3 (Selecting Pad: GPIO_SD_B1_{i-1:02} for Mode: ALT3); 1=GPIO_B0_{i+9}_ALT3 (Selecting Pad: GPIO_B0_{i+9} for Mode: ALT3)
0x5A4 SAI1_RX_SYNC_SELECT_INPUT — SAI1_RX_SYNC_SELECT_INPUT DAISY Register
  [1:0] DAISY — Selecting Pads Involved in Daisy Chain.
    0=GPIO_SD_B1_04_ALT3 (Selecting Pad: GPIO_SD_B1_04 for Mode: ALT3); 1=GPIO_AD_B1_10_ALT3 (Selecting Pad: GPIO_AD_B1_10 for Mode: ALT3); 2=GPIO_B0_14_ALT3 (Selecting Pad: GPIO_B0_14 for Mode: ALT3)
0x5A8 SAI1_TX_BCLK_SELECT_INPUT — SAI1_TX_BCLK_SELECT_INPUT DAISY Register
  [1:0] DAISY — Selecting Pads Involved in Daisy Chain.
    0=GPIO_SD_B1_08_ALT3 (Selecting Pad: GPIO_SD_B1_08 for Mode: ALT3); 1=GPIO_AD_B1_14_ALT3 (Selecting Pad: GPIO_AD_B1_14 for Mode: ALT3); 2=GPIO_B1_02_ALT3 (Selecting Pad: GPIO_B1_02 for Mode: ALT3)
0x5AC SAI1_TX_SYNC_SELECT_INPUT — SAI1_TX_SYNC_SELECT_INPUT DAISY Register
  [1:0] DAISY — Selecting Pads Involved in Daisy Chain.
    0=GPIO_SD_B1_09_ALT3 (Selecting Pad: GPIO_SD_B1_09 for Mode: ALT3); 1=GPIO_AD_B1_15_ALT3 (Selecting Pad: GPIO_AD_B1_15 for Mode: ALT3); 2=GPIO_B1_03_ALT3 (Selecting Pad: GPIO_B1_03 for Mode: ALT3)
0x5B0 SAI2_MCLK2_SELECT_INPUT — SAI2_MCLK2_SELECT_INPUT DAISY Register
  [0] DAISY — Selecting Pads Involved in Daisy Chain.
    0=GPIO_EMC_07_ALT2 (Selecting Pad: GPIO_EMC_07 for Mode: ALT2); 1=GPIO_AD_B0_10_ALT3 (Selecting Pad: GPIO_AD_B0_10 for Mode: ALT3)
0x5B4 SAI2_RX_BCLK_SELECT_INPUT — SAI2_RX_BCLK_SELECT_INPUT DAISY Register
  [0] DAISY — Selecting Pads Involved in Daisy Chain.
    0=GPIO_EMC_10_ALT2 (Selecting Pad: GPIO_EMC_10 for Mode: ALT2); 1=GPIO_AD_B0_06_ALT3 (Selecting Pad: GPIO_AD_B0_06 for Mode: ALT3)
0x5B8 SAI2_RX_DATA0_SELECT_INPUT — SAI2_RX_DATA0_SELECT_INPUT DAISY Register
  [0] DAISY — Selecting Pads Involved in Daisy Chain.
    0=GPIO_EMC_08_ALT2 (Selecting Pad: GPIO_EMC_08 for Mode: ALT2); 1=GPIO_AD_B0_08_ALT3 (Selecting Pad: GPIO_AD_B0_08 for Mode: ALT3)
0x5BC SAI2_RX_SYNC_SELECT_INPUT — SAI2_RX_SYNC_SELECT_INPUT DAISY Register
  [0] DAISY — Selecting Pads Involved in Daisy Chain.
    0=GPIO_EMC_09_ALT2 (Selecting Pad: GPIO_EMC_09 for Mode: ALT2); 1=GPIO_AD_B0_07_ALT3 (Selecting Pad: GPIO_AD_B0_07 for Mode: ALT3)
0x5C0 SAI2_TX_BCLK_SELECT_INPUT — SAI2_TX_BCLK_SELECT_INPUT DAISY Register
  [0] DAISY — Selecting Pads Involved in Daisy Chain.
    0=GPIO_EMC_06_ALT2 (Selecting Pad: GPIO_EMC_06 for Mode: ALT2); 1=GPIO_AD_B0_05_ALT3 (Selecting Pad: GPIO_AD_B0_05 for Mode: ALT3)
0x5C4 SAI2_TX_SYNC_SELECT_INPUT — SAI2_TX_SYNC_SELECT_INPUT DAISY Register
  [0] DAISY — Selecting Pads Involved in Daisy Chain.
    0=GPIO_EMC_05_ALT2 (Selecting Pad: GPIO_EMC_05 for Mode: ALT2); 1=GPIO_AD_B0_04_ALT3 (Selecting Pad: GPIO_AD_B0_04 for Mode: ALT3)
0x5C8 SPDIF_IN_SELECT_INPUT — SPDIF_IN_SELECT_INPUT DAISY Register
  [0] DAISY — Selecting Pads Involved in Daisy Chain.
    0=GPIO_AD_B1_03_ALT3 (Selecting Pad: GPIO_AD_B1_03 for Mode: ALT3); 1=GPIO_EMC_16_ALT3 (Selecting Pad: GPIO_EMC_16 for Mode: ALT3)
0x5CC USB_OTG2_OC_SELECT_INPUT — USB_OTG2_OC_SELECT_INPUT DAISY Register
  [0] DAISY — Selecting Pads Involved in Daisy Chain.
    0=GPIO_AD_B0_14_ALT0 (Selecting Pad: GPIO_AD_B0_14 for Mode: ALT0); 1=GPIO_EMC_40_ALT3 (Selecting Pad: GPIO_EMC_40 for Mode: ALT3)
0x5D0 USB_OTG1_OC_SELECT_INPUT — USB_OTG1_OC_SELECT_INPUT DAISY Register
  [0] DAISY — Selecting Pads Involved in Daisy Chain.
    0=GPIO_AD_B0_03_ALT3 (Selecting Pad: GPIO_AD_B0_03 for Mode: ALT3); 1=GPIO_AD_B1_03_ALT0 (Selecting Pad: GPIO_AD_B1_03 for Mode: ALT0)
0x5D4 USDHC1_CD_B_SELECT_INPUT — USDHC1_CD_B_SELECT_INPUT DAISY Register
  [1:0] DAISY — Selecting Pads Involved in Daisy Chain.
    0=GPIO_EMC_35_ALT6 (Selecting Pad: GPIO_EMC_35 for Mode: ALT6); 1=GPIO_AD_B1_02_ALT6 (Selecting Pad: GPIO_AD_B1_02 for Mode: ALT6); 2=GPIO_B1_12_ALT6 (Selecting Pad: GPIO_B1_12 for Mode: ALT6)
0x5D8 USDHC1_WP_SELECT_INPUT — USDHC1_WP_SELECT_INPUT DAISY Register
  [1:0] DAISY — Selecting Pads Involved in Daisy Chain.
    0=GPIO_EMC_12_ALT3 (Selecting Pad: GPIO_EMC_12 for Mode: ALT3); 1=GPIO_EMC_36_ALT6 (Selecting Pad: GPIO_EMC_36for Mode: ALT6); 2=GPIO_AD_B1_00_ALT6 (Selecting Pad:GPIO_AD_B1_00 for Mode: ALT6); 3=GPIO_B1_13_ALT6 (Selecting Pad: GPIO_B1_13 for Mode: ALT6)
0x5DC USDHC2_CLK_SELECT_INPUT — USDHC2_CLK_SELECT_INPUT DAISY Register
  [0] DAISY — Selecting Pads Involved in Daisy Chain.
    0=GPIO_SD_B1_04_ALT0 (Selecting Pad: GPIO_SD_B1_04 for Mode: ALT0); 1=GPIO_AD_B1_09_ALT6 (Selecting Pad: GPIO_AD_B1_09 for Mode: ALT6)
0x5E0 USDHC2_CD_B_SELECT_INPUT — USDHC2_CD_B_SELECT_INPUT DAISY Register
  [0] DAISY — Selecting Pads Involved in Daisy Chain.
    0=GPIO_AD_B1_03_ALT6 (Selecting Pad:GPIO_AD_B1_03 for Mode: ALT6); 1=GPIO_EMC_39_ALT6 (Selecting Pad: GPIO_EMC_39 for Mode: ALT6)
0x5E4 USDHC2_CMD_SELECT_INPUT — USDHC2_CMD_SELECT_INPUT DAISY Register
  [0] DAISY — Selecting Pads Involved in Daisy Chain.
    0=GPIO_SD_B1_05_ALT0 (Selecting Pad: GPIO_SD_B1_05 for Mode: ALT0); 1=GPIO_AD_B1_08_ALT6 (Selecting Pad: GPIO_AD_B1_08 for Mode: ALT6)
0x5E8 USDHC2_DATA0_SELECT_INPUT — USDHC2_DATA0_SELECT_INPUT DAISY Register
  [0] DAISY — Selecting Pads Involved in Daisy Chain.
    0=GPIO_SD_B1_03_ALT0 (Selecting Pad: GPIO_SD_B1_03 for Mode: ALT0); 1=GPIO_AD_B1_04_ALT6 (Selecting Pad:GPIO_AD_B1_04 for Mode: ALT6)
0x5EC USDHC2_DATA1_SELECT_INPUT — USDHC2_DATA1_SELECT_INPUT DAISY Register
  [0] DAISY — Selecting Pads Involved in Daisy Chain.
    0=GPIO_SD_B1_02_ALT0 (Selecting Pad: GPIO_SD_B1_02 for Mode: ALT0); 1=GPIO_AD_B1_05_ALT6 (Selecting Pad: GPIO_AD_B1_05 for Mode: ALT6)
0x5F0 USDHC2_DATA2_SELECT_INPUT — USDHC2_DATA2_SELECT_INPUT DAISY Register
  [0] DAISY — Selecting Pads Involved in Daisy Chain.
    0=GPIO_SD_B1_01_ALT0 (Selecting Pad: GPIO_SD_B1_01 for Mode: ALT0); 1=GPIO_AD_B1_06_ALT6 (Selecting Pad: GPIO_AD_B1_06 for Mode: ALT6)
0x5F4 USDHC2_DATA3_SELECT_INPUT — USDHC2_DATA3_SELECT_INPUT DAISY Register
  [0] DAISY — Selecting Pads Involved in Daisy Chain.
    0=GPIO_SD_B1_00_ALT0 (Selecting Pad: GPIO_SD_B1_00 for Mode: ALT0); 1=GPIO_AD_B1_07_ALT6 (Selecting Pad: GPIO_AD_B1_07 for Mode: ALT6)
{0x5E8+4i} USDHC2_DATA{i}_SELECT_INPUT (i=4..7) — USDHC2_DATA{i}_SELECT_INPUT DAISY Register
  [0] DAISY — Selecting Pads Involved in Daisy Chain.
    0=GPIO_SD_B1_{i+4:02}_ALT0 (Selecting Pad: GPIO_SD_B1_{i+4:02} for Mode: ALT0); 1=GPIO_AD_B1_{i+8}_ALT6 (Selecting Pad: GPIO_AD_B1_{i+8} for Mode: ALT6)
0x608 USDHC2_WP_SELECT_INPUT — USDHC2_WP_SELECT_INPUT DAISY Register
  [0] DAISY — Selecting Pads Involved in Daisy Chain.
    0=GPIO_EMC_37_ALT6 (Selecting Pad: GPIO_EMC_37 for Mode: ALT6); 1=GPIO_AD_B1_10_ALT6 (Selecting Pad: GPIO_AD_B1_10 for Mode: ALT6)
0x60C XBAR_INOUT02_SELECT_INPUT — XBAR_INOUT02_SELECT_INPUT DAISY Register
  [0] DAISY — Selecting Pads Involved in Daisy Chain.
    0=GPIO_EMC_00_ALT3 (Selecting Pad: GPIO_EMC_00 for Mode: ALT3); 1=GPIO_B1_14_ALT3 (Selecting Pad: GPIO_B1_14 for Mode: ALT3)
0x610 XBAR_INOUT03_SELECT_INPUT — XBAR_INOUT03_SELECT_INPUT DAISY Register
  [0] DAISY — Selecting Pads Involved in Daisy Chain.
    0=GPIO_EMC_01_ALT3 (Selecting Pad: GPIO_EMC_01 for Mode: ALT3); 1=GPIO_B1_15_ALT3 (Selecting Pad: GPIO_B1_15 for Mode: ALT3)
{0x604+4i} XBAR_INOUT{i:02}_SELECT_INPUT (i=4..9) — XBAR_INOUT{i:02}_SELECT_INPUT DAISY Register
  [0] DAISY — Selecting Pads Involved in Daisy Chain.
    0=GPIO_EMC_{i-2:02}_ALT3 (Selecting Pad: GPIO_EMC_{i-2:02} for Mode: ALT3); 1=GPIO_SD_B0_{i-4:02}_ALT3 (Selecting Pad: GPIO_SD_B0_{i-4:02} for Mode: ALT3)
0x62C XBAR_INOUT17_SELECT_INPUT — XBAR_INOUT17_SELECT_INPUT DAISY Register
  [1:0] DAISY — Selecting Pads Involved in Daisy Chain.
    0=GPIO_EMC_08_ALT3 (Selecting Pad: GPIO_EMC_08 for Mode: ALT3); 1=GPIO_AD_B0_03_ALT1 (Selecting Pad: GPIO_AD_B0_03 for Mode: ALT1); 2=GPIO_AD_B0_05_ALT6 (Selecting Pad: GPIO_AD_B0_05 for Mode: ALT6); 3=GPIO_B1_03_ALT1 (Selecting Pad: GPIO_B1_03 for Mode: ALT1)
0x630 XBAR_INOUT18_SELECT_INPUT — XBAR_INOUT18_SELECT_INPUT DAISY Register
  [0] DAISY — Selecting Pads Involved in Daisy Chain.
    0=GPIO_EMC_35_ALT1 (Selecting Pad: GPIO_EMC_35 for Mode: ALT1); 1=GPIO_AD_B0_06_ALT6 (Selecting Pad: GPIO_AD_B0_06 for Mode: ALT6)
0x634 XBAR_INOUT20_SELECT_INPUT — XBAR_INOUT20_SELECT_INPUT DAISY Register
  [0] DAISY — Selecting Pads Involved in Daisy Chain.
    0=GPIO_EMC_15_ALT1 (Selecting Pad: GPIO_EMC_15 for Mode: ALT1); 1=GPIO_AD_B0_08_ALT6 (Selecting Pad: GPIO_AD_B0_08 for Mode: ALT6)
0x638 XBAR_INOUT22_SELECT_INPUT — XBAR_INOUT22_SELECT_INPUT DAISY Register
  [0] DAISY — Selecting Pads Involved in Daisy Chain.
    0=GPIO_EMC_36_ALT1 (Selecting Pad: GPIO_EMC_36 for Mode: ALT1); 1=GPIO_AD_B0_10_ALT6 (Selecting Pad: GPIO_AD_B0_10 for Mode: ALT6)
0x63C XBAR_INOUT23_SELECT_INPUT — XBAR_INOUT23_SELECT_INPUT DAISY Register
  [0] DAISY — Selecting Pads Involved in Daisy Chain.
    0=GPIO_EMC_37_ALT1 (Selecting Pad: GPIO_EMC_37 for Mode: ALT1); 1=GPIO_AD_B0_11_ALT6 (Selecting Pad: GPIO_AD_B0_11 for Mode: ALT6)
0x640 XBAR_INOUT24_SELECT_INPUT — XBAR_INOUT24_SELECT_INPUT DAISY Register
  [0] DAISY — Selecting Pads Involved in Daisy Chain.
    0=GPIO_EMC_12_ALT1 (Selecting Pad: GPIO_EMC_12 for Mode: ALT1); 1=GPIO_AD_B0_14_ALT1 (Selecting Pad: GPIO_AD_B0_14 for Mode: ALT1)
0x644 XBAR_INOUT14_SELECT_INPUT — XBAR_INOUT14_SELECT_INPUT DAISY Register
  [0] DAISY — Selecting Pads Involved in Daisy Chain.
    0=GPIO_AD_B0_00_ALT1 (Selecting Pad: GPIO_AD_B0_00 for Mode: ALT1); 1=GPIO_B1_00_ALT1 (Selecting Pad:GPIO_B1_00 for Mode: ALT1)
0x648 XBAR_INOUT15_SELECT_INPUT — XBAR_INOUT15_SELECT_INPUT DAISY Register
  [0] DAISY — Selecting Pads Involved in Daisy Chain.
    0=GPIO_AD_B0_01_ALT1 (Selecting Pad: GPIO_AD_B0_01 for Mode: ALT1); 1=GPIO_B1_01_ALT1 (Selecting Pad: GPIO_B1_01 for Mode: ALT1)
0x64C XBAR_INOUT16_SELECT_INPUT — XBAR_INOUT16_SELECT_INPUT DAISY Register
  [0] DAISY — Selecting Pads Involved in Daisy Chain.
    0=GPIO_AD_B0_02_ALT1 (Selecting Pad: GPIO_AD_B0_02 for Mode: ALT1); 1=GPIO_B1_02_ALT1 (Selecting Pad: GPIO_B1_02 for Mode: ALT1)
0x650 XBAR_INOUT25_SELECT_INPUT — XBAR_INOUT25_SELECT_INPUT DAISY Register
  [0] DAISY — Selecting Pads Involved in Daisy Chain.
    0=GPIO_AD_B0_15_ALT1 (Selecting Pad: GPIO_AD_B0_15 for Mode: ALT1); 1=GPIO_EMC_13_ALT1 (Selecting Pad: GPIO_EMC_13 for Mode: ALT1)
0x654 XBAR_INOUT19_SELECT_INPUT — XBAR_INOUT19_SELECT_INPUT DAISY Register
  [0] DAISY — Selecting Pads Involved in Daisy Chain.
    0=GPIO_EMC_14_ALT1 (Selecting Pad: GPIO_EMC_14 for Mode: ALT1); 1=GPIO_AD_B0_07_ALT6 (Selecting Pad: GPIO_AD_B0_07 for Mode: ALT6)
0x658 XBAR_INOUT21_SELECT_INPUT — XBAR_INOUT23_SELECT_INPUT DAISY Register
  [0] DAISY — Selecting Pads Involved in Daisy Chain.
    0=GPIO_EMC_16_ALT1 (Selecting Pad: GPIO_EMC_16 for Mode: ALT1); 1=GPIO_AD_B0_09_ALT6 (Selecting Pad: GPIO_AD_B0_09 for Mode: ALT6)
